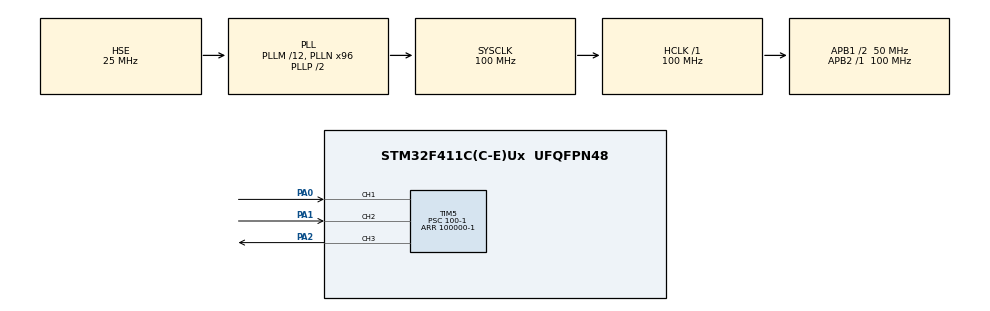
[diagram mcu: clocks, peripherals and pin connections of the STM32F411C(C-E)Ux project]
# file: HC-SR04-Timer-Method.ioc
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Dma.Request0=TIM5_CH1
Dma.Request1=TIM5_CH2
Dma.TIM5_CH1.0.Direction=DMA_PERIPH_TO_MEMORY
Dma.TIM5_CH1.0.FIFOMode=DMA_FIFOMODE_DISABLE
Dma.TIM5_CH1.0.Instance=DMA1_Stream2
Dma.TIM5_CH1.0.MemDataAlignment=DMA_MDATAALIGN_WORD
Dma.TIM5_CH1.0.MemInc=DMA_MINC_ENABLE
Dma.TIM5_CH1.0.Mode=DMA_CIRCULAR
Dma.TIM5_CH1.0.PeriphDataAlignment=DMA_PDATAALIGN_WORD
Dma.TIM5_CH1.0.PeriphInc=DMA_PINC_DISABLE
Dma.TIM5_CH1.0.Priority=DMA_PRIORITY_LOW
Dma.TIM5_CH2.1.Direction=DMA_PERIPH_TO_MEMORY
Dma.TIM5_CH2.1.FIFOMode=DMA_FIFOMODE_DISABLE
Dma.TIM5_CH2.1.Instance=DMA1_Stream4
Dma.TIM5_CH2.1.MemDataAlignment=DMA_MDATAALIGN_WORD
Dma.TIM5_CH2.1.MemInc=DMA_MINC_ENABLE
Dma.TIM5_CH2.1.Mode=DMA_CIRCULAR
Dma.TIM5_CH2.1.PeriphDataAlignment=DMA_PDATAALIGN_WORD
Dma.TIM5_CH2.1.PeriphInc=DMA_PINC_DISABLE
Dma.TIM5_CH2.1.Priority=DMA_PRIORITY_LOW
Mcu.Family=STM32F4
Mcu.Name=STM32F411C(C-E)Ux
Mcu.Package=UFQFPN48
NVIC.DMA1_Stream2_IRQn=true\:0\:0\:false\:false\:true\:false\:true\:true
NVIC.DMA1_Stream4_IRQn=true\:0\:0\:false\:false\:true\:false\:true\:true
NVIC.PriorityGroup=NVIC_PRIORITYGROUP_4
PA0-WKUP.Signal=S_TIM5_CH1
PA1.Signal=S_TIM5_CH2
PA13.Mode=Serial_Wire
PA13.Signal=SYS_JTMS-SWDIO
PA14.Mode=Serial_Wire
PA14.Signal=SYS_JTCK-SWCLK
PA2.Signal=S_TIM5_CH3
PH0\ -\ OSC_IN.Mode=HSE-External-Oscillator
PH0\ -\ OSC_IN.Signal=RCC_OSC_IN
PH1\ -\ OSC_OUT.Mode=HSE-External-Oscillator
PH1\ -\ OSC_OUT.Signal=RCC_OSC_OUT
ProjectManager.HeapSize=0x200
ProjectManager.StackSize=0x400
ProjectManager.TargetToolchain=STM32CubeIDE
RCC.48MHZClocksFreq_Value=50000000
RCC.AHBFreq_Value=100000000
RCC.APB1CLKDivider=RCC_HCLK_DIV2
RCC.APB1Freq_Value=50000000
RCC.APB1TimFreq_Value=100000000
RCC.APB2Freq_Value=100000000
RCC.APB2TimFreq_Value=100000000
RCC.CortexFreq_Value=100000000
RCC.HCLKFreq_Value=100000000
RCC.HSE_VALUE=25000000
RCC.HSI_VALUE=16000000
RCC.LSE_VALUE=32768
RCC.PLLM=12
RCC.PLLN=96
RCC.PLLSourceVirtual=RCC_PLLSOURCE_HSE
RCC.SYSCLKFreq_VALUE=100000000
RCC.SYSCLKSource=RCC_SYSCLKSOURCE_PLLCLK
RCC.VCOOutputFreq_Value=200000000
SH.S_TIM5_CH1.0=TIM5_CH1,Input_Capture1_from_TI1
SH.S_TIM5_CH2.0=TIM5_CH2,Input_Capture2_from_TI2
SH.S_TIM5_CH3.0=TIM5_CH3,PWM Generation3 CH3
TIM5.Channel-Input_Capture1_from_TI1=TIM_CHANNEL_1
TIM5.Channel-Input_Capture2_from_TI2=TIM_CHANNEL_2
TIM5.Channel-PWM\ Generation3\ CH3=TIM_CHANNEL_3
TIM5.ICPolarity_CH2=TIM_INPUTCHANNELPOLARITY_FALLING
TIM5.OCFastMode_PWM-PWM\ Generation3\ CH3=TIM_OCFAST_ENABLE
TIM5.Period=100000-1
TIM5.Prescaler=100-1
TIM5.Pulse-PWM\ Generation3\ CH3=10
VP_TIM5_VS_ClockSourceINT.Mode=Internal
board=custom

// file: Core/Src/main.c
/* USER CODE BEGIN Header */
/**
  ******************************************************************************
  * @file           : main.c
  * @brief          : Main program body
  ******************************************************************************
  * @attention
  *
  * Copyright (c) 2023 STMicroelectronics.
  * All rights reserved.
  *
  * This software is licensed under terms that can be found in the LICENSE file
  * in the root directory of this software component.
  * If no LICENSE file comes with this software, it is provided AS-IS.
  *
  ******************************************************************************
  */
/* USER CODE END Header */
#include "main.h"

/* USER CODE BEGIN PTD */
typedef struct{
	uint32_t RisingTiming;
	uint32_t FallingTiming;
	double DistanceInCm;
	double DistanceInInches;

	TIM_HandleTypeDef *htim;
	uint32_t PWM_Channel;
	uint32_t RisingIChannel;
	uint32_t FallingIChannel;
}HCSR04_t;
/* USER CODE END PTD */

TIM_HandleTypeDef htim5;
DMA_HandleTypeDef hdma_tim5_ch1;
DMA_HandleTypeDef hdma_tim5_ch2;

/* USER CODE BEGIN PV */
HCSR04_t Hcsr04;
/* USER CODE END PV */

void SystemClock_Config(void);
static void MX_GPIO_Init(void);
static void MX_DMA_Init(void);
static void MX_TIM5_Init(void);

/* USER CODE BEGIN 0 */

uint32_t _get_tim_active_channel(uint32_t channel){
	switch (channel){
	case TIM_CHANNEL_1:
		return HAL_TIM_ACTIVE_CHANNEL_1;
	case TIM_CHANNEL_2:
		return HAL_TIM_ACTIVE_CHANNEL_2;
	case TIM_CHANNEL_3:
		return HAL_TIM_ACTIVE_CHANNEL_3;
	case TIM_CHANNEL_4:
		return HAL_TIM_ACTIVE_CHANNEL_4;
	default:
		return 0;
	}
}
// callbacks

void HAL_TIM_IC_CaptureCallback(TIM_HandleTypeDef *htim){
	if (htim->Instance == Hcsr04.htim->Instance){
		// Gets the ACtive Channel parameter and check if the interrupt as came
		// from the Falling Edge Interrupt Capture Channel
		if (htim->Channel == _get_tim_active_channel(Hcsr04.FallingIChannel)){
			Hcsr04.DistanceInCm = (double)((Hcsr04.FallingTiming-Hcsr04.RisingTiming)/58.0);
			Hcsr04.DistanceInInches = (double)((Hcsr04.FallingTiming-Hcsr04.RisingTiming)/148.0);
		}
	}
}

// functions
void _hcsr04_init(HCSR04_t *handle){
	handle->DistanceInCm = 400;
	HAL_TIM_PWM_Start(handle->htim, handle->PWM_Channel);
	HAL_TIM_IC_Start_DMA(handle->htim, handle->RisingIChannel, &handle->RisingTiming, 1);
	HAL_TIM_IC_Start_DMA(handle->htim, handle->FallingIChannel, &handle->FallingTiming, 1);
}

double _hcsr04_get_distance_incm(HCSR04_t *handle){
	return handle->DistanceInCm;
}
/* USER CODE END 0 */

int main(void)
{

  /* MCU Configuration--------------------------------------------------------*/

  /* Reset of all peripherals, Initializes the Flash interface and the Systick. */
  HAL_Init();

  /* Configure the system clock */
  SystemClock_Config();

  /* Initialize all configured peripherals */
  MX_GPIO_Init();
  MX_DMA_Init();
  MX_TIM5_Init();
  /* USER CODE BEGIN 2 */
  Hcsr04.htim = &htim5;
  Hcsr04.PWM_Channel = TIM_CHANNEL_3;
  Hcsr04.FallingIChannel = TIM_CHANNEL_2;
  Hcsr04.RisingIChannel = TIM_CHANNEL_1;
  _hcsr04_init(&Hcsr04);
  /* USER CODE END 2 */

  /* Infinite loop */
  while (1)
  {

  }
}

void SystemClock_Config(void)
{
  RCC_OscInitTypeDef RCC_OscInitStruct = {0};
  RCC_ClkInitTypeDef RCC_ClkInitStruct = {0};

  /** Configure the main internal regulator output voltage
  */
  __HAL_RCC_PWR_CLK_ENABLE();
  __HAL_PWR_VOLTAGESCALING_CONFIG(PWR_REGULATOR_VOLTAGE_SCALE1);

  /** Initializes the RCC Oscillators according to the specified parameters
  * in the RCC_OscInitTypeDef structure.
  */
  RCC_OscInitStruct.OscillatorType = RCC_OSCILLATORTYPE_HSE;
  RCC_OscInitStruct.HSEState = RCC_HSE_ON;
  RCC_OscInitStruct.PLL.PLLState = RCC_PLL_ON;
  RCC_OscInitStruct.PLL.PLLSource = RCC_PLLSOURCE_HSE;
  RCC_OscInitStruct.PLL.PLLM = 12;
  RCC_OscInitStruct.PLL.PLLN = 96;
  RCC_OscInitStruct.PLL.PLLP = RCC_PLLP_DIV2;
  RCC_OscInitStruct.PLL.PLLQ = 4;
  if (HAL_RCC_OscConfig(&RCC_OscInitStruct) != HAL_OK)
  {
    Error_Handler();
  }

  /** Initializes the CPU, AHB and APB buses clocks
  */
  RCC_ClkInitStruct.ClockType = RCC_CLOCKTYPE_HCLK|RCC_CLOCKTYPE_SYSCLK
                              |RCC_CLOCKTYPE_PCLK1|RCC_CLOCKTYPE_PCLK2;
  RCC_ClkInitStruct.SYSCLKSource = RCC_SYSCLKSOURCE_PLLCLK;
  RCC_ClkInitStruct.AHBCLKDivider = RCC_SYSCLK_DIV1;
  RCC_ClkInitStruct.APB1CLKDivider = RCC_HCLK_DIV2;
  RCC_ClkInitStruct.APB2CLKDivider = RCC_HCLK_DIV1;

  if (HAL_RCC_ClockConfig(&RCC_ClkInitStruct, FLASH_LATENCY_3) != HAL_OK)
  {
    Error_Handler();
  }
}

static void MX_TIM5_Init(void)
{

  TIM_ClockConfigTypeDef sClockSourceConfig = {0};
  TIM_MasterConfigTypeDef sMasterConfig = {0};
  TIM_IC_InitTypeDef sConfigIC = {0};
  TIM_OC_InitTypeDef sConfigOC = {0};

  htim5.Instance = TIM5;
  htim5.Init.Prescaler = 100-1;
  htim5.Init.CounterMode = TIM_COUNTERMODE_UP;
  htim5.Init.Period = 100000-1;
  htim5.Init.ClockDivision = TIM_CLOCKDIVISION_DIV1;
  htim5.Init.AutoReloadPreload = TIM_AUTORELOAD_PRELOAD_DISABLE;
  if (HAL_TIM_Base_Init(&htim5) != HAL_OK)
  {
    Error_Handler();
  }
  sClockSourceConfig.ClockSource = TIM_CLOCKSOURCE_INTERNAL;
  if (HAL_TIM_ConfigClockSource(&htim5, &sClockSourceConfig) != HAL_OK)
  {
    Error_Handler();
  }
  if (HAL_TIM_IC_Init(&htim5) != HAL_OK)
  {
    Error_Handler();
  }
  if (HAL_TIM_PWM_Init(&htim5) != HAL_OK)
  {
    Error_Handler();
  }
  sMasterConfig.MasterOutputTrigger = TIM_TRGO_RESET;
  sMasterConfig.MasterSlaveMode = TIM_MASTERSLAVEMODE_DISABLE;
  if (HAL_TIMEx_MasterConfigSynchronization(&htim5, &sMasterConfig) != HAL_OK)
  {
    Error_Handler();
  }
  sConfigIC.ICPolarity = TIM_INPUTCHANNELPOLARITY_RISING;
  sConfigIC.ICSelection = TIM_ICSELECTION_DIRECTTI;
  sConfigIC.ICPrescaler = TIM_ICPSC_DIV1;
  sConfigIC.ICFilter = 0;
  if (HAL_TIM_IC_ConfigChannel(&htim5, &sConfigIC, TIM_CHANNEL_1) != HAL_OK)
  {
    Error_Handler();
  }
  sConfigIC.ICPolarity = TIM_INPUTCHANNELPOLARITY_FALLING;
  if (HAL_TIM_IC_ConfigChannel(&htim5, &sConfigIC, TIM_CHANNEL_2) != HAL_OK)
  {
    Error_Handler();
  }
  sConfigOC.OCMode = TIM_OCMODE_PWM1;
  sConfigOC.Pulse = 10;
  sConfigOC.OCPolarity = TIM_OCPOLARITY_HIGH;
  sConfigOC.OCFastMode = TIM_OCFAST_ENABLE;
  if (HAL_TIM_PWM_ConfigChannel(&htim5, &sConfigOC, TIM_CHANNEL_3) != HAL_OK)
  {
    Error_Handler();
  }
  HAL_TIM_MspPostInit(&htim5);

}

static void MX_DMA_Init(void)
{

  /* DMA controller clock enable */
  __HAL_RCC_DMA1_CLK_ENABLE();

  /* DMA interrupt init */
  /* DMA1_Stream2_IRQn interrupt configuration */
  HAL_NVIC_SetPriority(DMA1_Stream2_IRQn, 0, 0);
  HAL_NVIC_EnableIRQ(DMA1_Stream2_IRQn);
  /* DMA1_Stream4_IRQn interrupt configuration */
  HAL_NVIC_SetPriority(DMA1_Stream4_IRQn, 0, 0);
  HAL_NVIC_EnableIRQ(DMA1_Stream4_IRQn);

}

static void MX_GPIO_Init(void)
{

  /* GPIO Ports Clock Enable */
  __HAL_RCC_GPIOH_CLK_ENABLE();
  __HAL_RCC_GPIOA_CLK_ENABLE();

}

void Error_Handler(void)
{
  __disable_irq();
  while (1)
  {
  }
}
